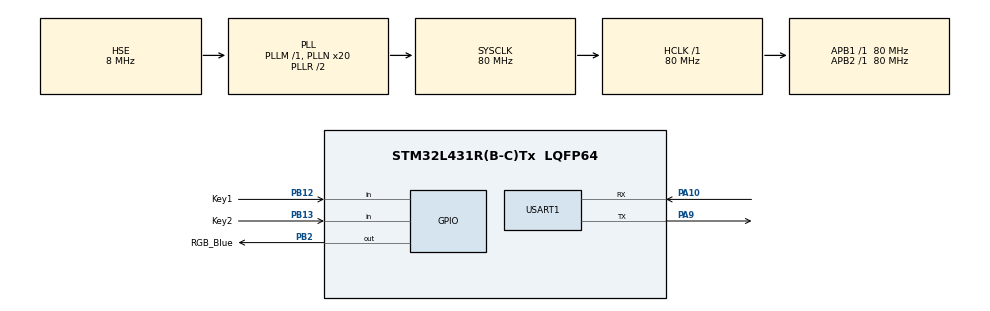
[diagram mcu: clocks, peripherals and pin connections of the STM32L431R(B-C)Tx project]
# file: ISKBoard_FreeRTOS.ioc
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FREERTOS.Tasks01=defaultTask,24,128,StartDefaultTask,Default,NULL,Dynamic,NULL,NULL
Mcu.Family=STM32L4
Mcu.Name=STM32L431R(B-C)Tx
Mcu.Package=LQFP64
NVIC.PriorityGroup=NVIC_PRIORITYGROUP_4
NVIC.TIM7_IRQn=true\:15\:0\:false\:false\:true\:false\:false\:true\:true
NVIC.TimeBase=TIM7_IRQn
NVIC.TimeBaseIP=TIM7
PA10.Mode=Asynchronous
PA10.Signal=USART1_RX
PA9.Mode=Asynchronous
PA9.Signal=USART1_TX
PB12.GPIO_Label=Key1
PB12.Signal=GPIO_Input
PB13.GPIO_Label=Key2
PB13.Signal=GPIO_Input
PB2.GPIO_Label=RGB_Blue
PB2.PinState=GPIO_PIN_SET
PB2.Signal=GPIO_Output
PH0-OSC_IN\ (PH0).Mode=HSE-External-Oscillator
PH0-OSC_IN\ (PH0).Signal=RCC_OSC_IN
PH1-OSC_OUT\ (PH1).Mode=HSE-External-Oscillator
PH1-OSC_OUT\ (PH1).Signal=RCC_OSC_OUT
ProjectManager.HeapSize=0x200
ProjectManager.StackSize=0x400
ProjectManager.TargetToolchain=STM32CubeIDE
RCC.ADCFreq_Value=32000000
RCC.AHBFreq_Value=80000000
RCC.APB1Freq_Value=80000000
RCC.APB1TimFreq_Value=80000000
RCC.APB2Freq_Value=80000000
RCC.APB2TimFreq_Value=80000000
RCC.CortexFreq_Value=80000000
RCC.HCLKFreq_Value=80000000
RCC.HSE_VALUE=8000000
RCC.HSI48_VALUE=48000000
RCC.HSI_VALUE=16000000
RCC.LSE_VALUE=32768
RCC.MSI_VALUE=4000000
RCC.PLLN=20
RCC.PLLSourceVirtual=RCC_PLLSOURCE_HSE
RCC.SYSCLKFreq_VALUE=80000000
RCC.SYSCLKSource=RCC_SYSCLKSOURCE_PLLCLK
RCC.VCOOutputFreq_Value=160000000
USART1.VirtualMode-Asynchronous=VM_ASYNC
VP_FREERTOS_VS_CMSIS_V2.Mode=CMSIS_V2
VP_SYS_VS_tim7.Mode=TIM7
board=custom

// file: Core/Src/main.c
/* USER CODE BEGIN Header */
/**
  ******************************************************************************
  * @file           : main.c
  * @brief          : Main program body
  ******************************************************************************
  * @attention
  *
  * Copyright (c) 2025 STMicroelectronics.
  * All rights reserved.
  *
  * This software is licensed under terms that can be found in the LICENSE file
  * in the root directory of this software component.
  * If no LICENSE file comes with this software, it is provided AS-IS.
  *
  ******************************************************************************
  */
/* USER CODE END Header */
#include "main.h"
#include "cmsis_os.h"
#include "usart.h"
#include "gpio.h"

/* USER CODE BEGIN Includes */
#include "core.h"
#include "miscdev.h"
/* USER CODE END Includes */

void SystemClock_Config(void);
void MX_FREERTOS_Init(void);

int main(void)
{

  /* MCU Configuration--------------------------------------------------------*/

  /* Reset of all peripherals, Initializes the Flash interface and the Systick. */
  HAL_Init();

  /* Configure the system clock */
  SystemClock_Config();

  /* Initialize all configured peripherals */
  MX_GPIO_Init();
  MX_USART1_UART_Init();
  /* USER CODE BEGIN 2 */

  printf("Welcome to FreeRTOS test project!\r\n");

  /* 启动FreeRTOS应用 */
  FreeRTOS_App_Init();

  /* USER CODE END 2 */

  /* Init scheduler */
  osKernelInitialize();  /* Call init function for freertos objects (in cmsis_os2.c) */
  MX_FREERTOS_Init();

  /* Start scheduler */
  printf("--- Start scheduler use func osKernelStart in main ---\n");
  osKernelStart();
  /* We should never get here as control is now taken by the scheduler */

  /* Infinite loop */
  while (1)
  {

  }
}

void SystemClock_Config(void)
{
  RCC_OscInitTypeDef RCC_OscInitStruct = {0};
  RCC_ClkInitTypeDef RCC_ClkInitStruct = {0};

  /** Configure the main internal regulator output voltage
  */
  if (HAL_PWREx_ControlVoltageScaling(PWR_REGULATOR_VOLTAGE_SCALE1) != HAL_OK)
  {
    Error_Handler();
  }

  /** Initializes the RCC Oscillators according to the specified parameters
  * in the RCC_OscInitTypeDef structure.
  */
  RCC_OscInitStruct.OscillatorType = RCC_OSCILLATORTYPE_HSE;
  RCC_OscInitStruct.HSEState = RCC_HSE_ON;
  RCC_OscInitStruct.PLL.PLLState = RCC_PLL_ON;
  RCC_OscInitStruct.PLL.PLLSource = RCC_PLLSOURCE_HSE;
  RCC_OscInitStruct.PLL.PLLM = 1;
  RCC_OscInitStruct.PLL.PLLN = 20;
  RCC_OscInitStruct.PLL.PLLP = RCC_PLLP_DIV7;
  RCC_OscInitStruct.PLL.PLLQ = RCC_PLLQ_DIV2;
  RCC_OscInitStruct.PLL.PLLR = RCC_PLLR_DIV2;
  if (HAL_RCC_OscConfig(&RCC_OscInitStruct) != HAL_OK)
  {
    Error_Handler();
  }

  /** Initializes the CPU, AHB and APB buses clocks
  */
  RCC_ClkInitStruct.ClockType = RCC_CLOCKTYPE_HCLK|RCC_CLOCKTYPE_SYSCLK
                              |RCC_CLOCKTYPE_PCLK1|RCC_CLOCKTYPE_PCLK2;
  RCC_ClkInitStruct.SYSCLKSource = RCC_SYSCLKSOURCE_PLLCLK;
  RCC_ClkInitStruct.AHBCLKDivider = RCC_SYSCLK_DIV1;
  RCC_ClkInitStruct.APB1CLKDivider = RCC_HCLK_DIV1;
  RCC_ClkInitStruct.APB2CLKDivider = RCC_HCLK_DIV1;

  if (HAL_RCC_ClockConfig(&RCC_ClkInitStruct, FLASH_LATENCY_4) != HAL_OK)
  {
    Error_Handler();
  }
}

void HAL_TIM_PeriodElapsedCallback(TIM_HandleTypeDef *htim)
{
  if (htim->Instance == TIM7)
  {
    HAL_IncTick();
  }
}

void Error_Handler(void)
{
  __disable_irq();
  while (1)
  {
  }
}

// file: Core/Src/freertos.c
/* USER CODE BEGIN Header */
/**
  ******************************************************************************
  * File Name          : freertos.c
  * Description        : Code for freertos applications
  ******************************************************************************
  * @attention
  *
  * Copyright (c) 2025 STMicroelectronics.
  * All rights reserved.
  *
  * This software is licensed under terms that can be found in the LICENSE file
  * in the root directory of this software component.
  * If no LICENSE file comes with this software, it is provided AS-IS.
  *
  ******************************************************************************
  */
/* USER CODE END Header */

#include "FreeRTOS.h"
#include "task.h"
#include "main.h"
#include "cmsis_os.h"

/* USER CODE BEGIN Includes */
#include "core.h"
/* USER CODE END Includes */

/* Definitions for defaultTask */
osThreadId_t defaultTaskHandle;
const osThreadAttr_t defaultTask_attributes = {
  .name = "defaultTask",
  .stack_size = 128 * 4,
  .priority = (osPriority_t) osPriorityNormal,
};

void StartDefaultTask(void *argument);

void MX_FREERTOS_Init(void); /* (MISRA C 2004 rule 8.1) */

void MX_FREERTOS_Init(void) {

  /* Create the thread(s) */
  /* creation of defaultTask */
  defaultTaskHandle = osThreadNew(StartDefaultTask, NULL, &defaultTask_attributes);

}

void StartDefaultTask(void *argument)
{
  for(;;)
  {
    osDelay(1);
  }
}
